# pse84_a0 register map
Vendor: Infineon Technologies; Series: PSE84_A0; File version: 1.0
CPU: CM33 r0p1, little endian, MPU, FPU, VTOR, 3 interrupt priority bits
Registers are 32-bit, read-write, reset 0x0 unless marked. A register's access mark holds for its fields unless they carry their own. Offsets are from the block's base; [hi:lo] are bit positions; lines under a group give offsets from that group; {n}, {i} and the like mark numbered series.

## USBHS (part 2 of 7) — Regmap for both Subsystem and Controller IP
Base 0x44900000
0x00 DWC_OTG_INTREG group — Internal register map
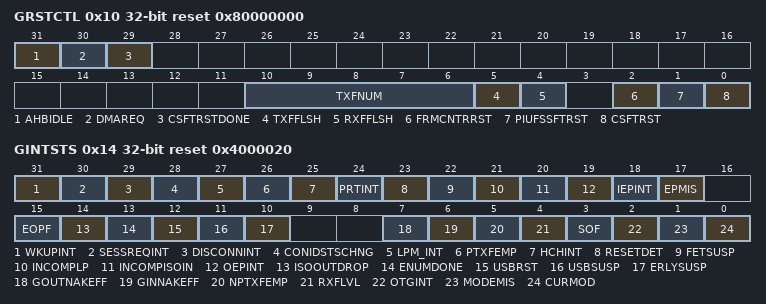
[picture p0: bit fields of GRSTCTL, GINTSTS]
  0x10 GRSTCTL reset 0x80000000 — The application uses this register to reset various hardware features inside the controller.
    [31] AHBIDLE ro — Mode: Host and Device AHB Master Idle (AHBIdle) Indicates that the AHB Master State Machine is in the IDLE condition.
      1=ACTIVE (AHB Master Idle); 0=INACTIVE (Not Idle)
    [30] DMAREQ ro — Mode: Host and Device DMA Request Signal (DMAReq) Indicates that the DMA request is in progress. Used for debug.
      1=ACTIVE (DMA request is in progress); 0=INACTIVE (No DMA request)
    [29] CSFTRSTDONE — Mode: Host and Device Core Soft Reset Done (CSftRstDone) The core sets this bit when all the necessary logic is reset in the core.This bit is cleared by the application along with GRSTCTL.CSftRst (bit 0)
      1=ACTIVE (Core Soft Reset is done); 0=INACTIVE (No reset)
    [10:6] TXFNUM — Mode: Host and Device TxFIFO Number (TxFNum) This is the FIFO number that must be flushed using the TxFIFO Flush bit. This field must not be changed until the core clears the TxFIFO Flush bit. - 5'h0: -- Non-periodic TxFIFO flush in Host mode -- Non-periodic TxFIFO flush in device mode when in shared FIFO operation -- Tx FIFO 0 flush in device mode when in dedicated FIFO mode - 5'h1: -- Periodic TxFIFO flush in Host mode -- Periodic TxFIFO 1 flush in Device mode when in shared FIFO operation -- TXFIFO 1 flush in device mode when in dedicated FIFO mode - 5'h2: -- Periodic TxFIFO 2 flush in Device mode when in shared FIFO operation -- TXFIFO 2 flush in device mode when in dedicated FIFO mode ... - 5'hF -- Periodic TxFIFO 15 flush in Device mode when in shared FIFO operation -- TXFIFO 15 flush in device mode when in dedicated FIFO mode - 5'h10: Flush all the transmit FIFOs in device or host mode
      0=TXF0 (<ct:DWC_DESIGN_ID==0>-Periodic TxFIFO flush in host mode -Periodic TxFIFO 0 flush in device mode when in shared FIFO operation -</ct>TXFIFO 0 flush in device mode when in dedicated FIFO mode); 1=TXF1 (<ct:DWC_DESIGN_ID==0>-Periodic TxFIFO flush in host mode -Periodic TxFIFO 1 flush in device mode when in shared FIFO operation -</ct>TXFIFO 1 flush in device mode when in dedicated FIFO mode); {v}=TXF{v} (-Periodic TxFIFO {v} flush in device mode when in shared FIFO operation -TXFIFO {v} flush in device mode when in dedicated FIFO mode) (v=9..12); 13=TXF13 (-Periodic TxFIFO 13 flush in Device mode when in shared FIFO operation -TXFIFO 13 flush in device mode when in dedicated FIFO mode); 14=TXF14 (-Periodic TxFIFO 14 flush in Device mode when in shared FIFO operation -TXFIFO 14 flush in device mode when in dedicated FIFO mode); 15=TXF15 (-Periodic TxFIFO 15 flush in Device mode when in shared FIFO operation - TXFIFO 15 flush in device mode when in dedicated FIFO mode); 16=TXF16 (Flush all the transmit FIFOs<ct:DWC_DESIGN_ID==0> in device or host mode</ct>); {v}=TXF{v} (<ct:DWC_DESIGN_ID==0>-Periodic TxFIFO {v} flush in device mode when in shared FIFO operation -</ct>TXFIFO {v} flush in device mode when in dedicated FIFO mode) (v=2..8)
    [5] TXFFLSH — Mode: Host and Device TxFIFO Flush (TxFFlsh) This bit selectively flushes a single or all transmit FIFOs, but cannot do so If the core is in the midst of a transaction. The application must write this bit only after checking that the core is neither writing to the TxFIFO nor reading from the TxFIFO. Verify using these registers: - ReadNAK Effective Interrupt ensures the core is not reading from the FIFO - WriteGRSTCTL.AHBIdle ensures the core is not writing anything to the FIFO. Flushing is normally recommended when FIFOs are reconfigured or when switching between Shared FIFO and Dedicated Transmit FIFO operation. FIFO flushing is also recommended during device endpoint disable. The application must wait until the core clears this bit before performing any operations. This bit takes eight clocks to clear, using the slower clock of phy_clk or hclk.
      1=ACTIVE (Selectively flushes a single or all transmit FIFOs); 0=INACTIVE (No Flush)
    [4] RXFFLSH — Mode: Host and Device RxFIFO Flush (RxFFlsh) The application can flush the entire RxFIFO using this bit, but must first ensure that the core is not in the middle of a transaction. The application must only write to this bit after checking that the controller is neither reading from the RxFIFO nor writing to the RxFIFO. The application must wait until the bit is cleared before performing any other operations. This bit requires eight clocks (slowest of PHY or AHB clock) to clear.
      1=ACTIVE (Flushes the entire RxFIFO); 0=INACTIVE (Does not flush the entire RxFIFO)
    [2] FRMCNTRRST — Mode: Host only Host Frame Counter Reset (FrmCntrRst) The application writes this bit to reset the (micro)Frame number counter inside the core. When the (micro)Frame counter is reset, the subsequent SOF sent out by the core has a (micro)Frame number of 0. When application writes 1 to the bit, it might not be able to read back the value as it will get cleared by the core in a few clock cycles.
      1=ACTIVE (Host Frame Counter Reset); 0=NOTACTIVE (No reset)
    [1] PIUFSSFTRST — Mode: Host and Device PIU FS Dedicated Controller Soft Reset (PIUFSSftRst) Resets the PIU FS Dedicated Controller All module state machines in FS Dedicated Controller of PIU are reset to the IDLE state. Used to reset the FS Dedicated controller in PIU in case of any PHY Errors like Loss of activity or Babble Error resulting in the PHY remaining in RX state for more than one frame boundary. This is a self clearing bit and core clears this bit after all the necessary logic is reset in the core.
      1=RESET_ACTIVE (PIU FS Dedicated Controller Soft Reset); 0=RESET_INACTIVE (No Reset)
    [0] CSFTRST — Mode: Host and Device Core Soft Reset (CSftRst) Resets the hclk and phy_clock domains as follows: - Clears the interrupts and all the CSR registers except the following register bits: -- PCGCCTL.RstPdwnModule -- PCGCCTL.GateHclk -- PCGCCTL.PwrClmp -- PCGCCTL.StopPPhyLPwrClkSelclk -- GUSBCFG.ForceDevMode -- GUSBCFG.ForceHstMode -- GUSBCFG.PhyLPwrClkSel -- GUSBCFG.DDRSel -- GUSBCFG.PHYSel -- GUSBCFG.FSIntf -- GUSBCFG.ULPI_UTMI_Sel -- GUSBCFG.PHYIf -- GUSBCFG.TxEndDelay -- GUSBCFG.TermSelDLPulse -- GUSBCFG.ULPIClkSusM -- GUSBCFG.ULPIAutoRes -- GUSBCFG.ULPIFsLs -- GGPIO -- GPWRDN -- GADPCTL -- HCFG.FSLSPclkSel -- DCFG.DevSpd -- DCTL.SftDiscon - All module state machines - All module state machines (except the AHB Slave Unit) are reset to the IDLE state, and all the transmit FIFOs and the receive FIFO are flushed. - Any transactions on the AHB Master are terminated as soon as possible, after gracefully completing the last data phase of an AHB transfer. Any transactions on the USB are terminated immediately. - When Hibernation or ADP feature is enabled, the PMU module is not reset by the Core Soft Reset. The application can write to this bit any time it wants to reset the core. The application must clear this bit after checking the bit 29 of this regiser (Core Soft Reset Done). Software must also must check that bit 31 of this register is 1 (AHB Master is IDLE) before starting any operation. Typically software reset is used during software development and also when you dynamically change the PHY selection bits in the USB configuration registers listed above. When you change the PHY, the corresponding clock for the PHY is selected and used in the PHY domain. Once a new clock is selected, the PHY domain has to be reset for proper operation.
      1=ACTIVE (Resets hclk and phy_clock domains); 0=NOTACTIVE (No reset)
  0x14 GINTSTS reset 0x4000020 — This register interrupts the application for system-level events in the current mode (Device mode or Host mode). Some of the bits in this register are valid only in Host mode, while others are valid in Device mode only. This register also indicates the current mode. To clear the interrupt status bits of type R_SS_WC, the application must write 1'b1 to the bit. The FIFO status interrupts are read only; once software reads from or writes to the FIFO while servicing these interrupts, FIFO interrupt conditions are cleared automatically. The application must clear the GINTSTS register at initialization before unmasking the interrupt bit to avoid any interrupts generated prior to initialization. Note: Read the reset value of GINTSTS.CurMod only after the following conditions: - If IDDIG_FILTER is disabled, read only after PHY clock is stable. - If IDDIG_FILTER is enabled, read only after the filter timer expires.
    [31] WKUPINT — Mode: Host and Device Resume/Remote Wakeup Detected Interrupt (WkUpInt) Wakeup Interrupt during Suspend(L2) or LPM(L1) state. - During Suspend(L2): -- Device Mode: This interrupt is asserted only when Host Initiated Resume is detected on USB. -- Host Mode: This interrupt is asserted only when Device Initiated Remote Wakeup is detected on USB. For more information, see 'Partial Power-Down and Clock Gating Programming Model' in the Programming Guide. - During LPM(L1): -- Device Mode: This interrupt is asserted for either Host Initiated Resume or Device Initiated Remote Wakeup on USB. -- Host Mode: This interrupt is asserted for either Host Initiated Resume or Device Initiated Remote Wakeup on USB. For more information, see 'LPM Entry and Exit Programming Model' in the Programming Guide.
      1=ACTIVE (Resume or Remote Wakeup Detected Interrupt); 0=INACTIVE (Not active)
    [30] SESSREQINT — Mode: Host and Device Session Request/New Session Detected Interrupt (SessReqInt) In Host mode, this interrupt is asserted when a session request is detected from the device. In Host mode, this interrupt is asserted when a session request is detected from the device. In Device mode, this interrupt is asserted when the utmisrp_bvalid signal goes high. For more information on how to use this interrupt, see 'Partial Power-Down and Clock Gating Programming Model' in the Programming Guide.
      1=ACTIVE (Session Request New Session Detected Interrupt); 0=INACTIVE (Not active)
    [29] DISCONNINT — Mode: Host only Disconnect Detected Interrupt (DisconnInt) Asserted when a device disconnect is detected.
      1=ACTIVE (Disconnect Detected Interrupt); 0=INACTIVE (Not active)
    [28] CONIDSTSCHNG — Mode: Host and Device Connector ID Status Change (ConIDStsChng) The core sets this bit when there is a change in connector ID status.
      1=ACTIVE (Connector ID Status Change); 0=INACTIVE (Not Active)
    [27] LPM_INT — Mode: Host and Device LPM Transaction Received Interrupt (LPM_Int). - Device Mode: This interrupt is asserted when the device receives an LPM transaction and responds with a non-ERRORed response. - Host Mode: This interrupt is asserted when the device responds to an LPM transaction with a non-ERRORed response or when the host core has completed LPM transactions for the programmed number of times (GLPMCFG.RetryCnt).
      1=ACTIVE (LPM Transaction Received Interrupt); 0=INACTIVE (Not Active)
    [26] PTXFEMP ro — Mode: Host only Periodic TxFIFO Empty (PTxFEmp) This interrupt is asserted when the Periodic Transmit FIFO is either half or completely empty and there is space for at least one entry to be written in the Periodic Request Queue. The half or completely empty status is determined by the Periodic TxFIFO Empty Level bit in the Core AHB Configuration register (GAHBCFG.PTxFEmpLvl).
      1=ACTIVE (Periodic TxFIFO Empty); 0=INACTIVE (Not active)
    [25] HCHINT ro — Mode: Host only Host Channels Interrupt (HChInt) The core sets this bit to indicate that an interrupt is pending on one of the channels of the core (in Host mode). The application must read the Host All Channels Interrupt (HAINT) register to determine the exact number of the channel on which the interrupt occurred, and Then read the corresponding Host Channel-n Interrupt (HCINTn) register to determine the exact cause of the interrupt. The application must clear the appropriate status bit in the HCINTn register to clear this bit.
      1=ACTIVE (Host Channels Interrupt); 0=INACTIVE (Not active)
    [24] PRTINT ro — Mode: Host only Host Port Interrupt (PrtInt) The core sets this bit to indicate a change in port status of one of the controller ports in Host mode. The application must read the Host Port Control and Status (HPRT) register to determine the exact event that caused this interrupt. The application must clear the appropriate status bit in the Host Port Control and Status register to clear this bit.
      1=ACTIVE (Host Port Interrupt); 0=INACTIVE (Not active)
    [23] RESETDET — Mode: Device only Reset detected Interrupt (ResetDet) In Device mode, this interrupt is asserted when a reset is detected on the USB in partial power-down mode when the device is in Suspend. In Host mode, this interrupt is not asserted.
      1=ACTIVE (Reset detected Interrupt); 0=INACTIVE (Not active)
    [22] FETSUSP — Mode: Device only Data Fetch Suspended (FetSusp) This interrupt is valid only in DMA mode. This interrupt indicates that the core has stopped fetching data. For IN endpoints due to the unavailability of TxFIFO space or Request Queue space. This interrupt is used by the application for an endpoint mismatch algorithm. For example, after detecting an endpoint mismatch, the application: - Sets a Global non-periodic IN NAK handshake - Disables IN endpoints - Flushes the FIFO - Determines the token sequence from the IN Token Sequence Learning Queue - Re-enables the endpoints - Clears the Global non-periodic IN NAK handshake If the Global non-periodic IN NAK is cleared, the core has not yet fetched data for the IN endpoint, and the IN token is received. The core generates an 'IN token received when FIFO empty' interrupt. It then sends the host a NAK response. To avoid this scenario, the application can check the GINTSTS.FetSusp interrupt, which ensures that the FIFO is full before clearing a Global NAK handshake. Alternatively, the application can mask the IN token received when FIFO empty interrupt when clearing a Global IN NAK handshake.
      1=ACTIVE (Data Fetch Suspended); 0=INACTIVE (Not active)
    [21] INCOMPLP — Incomplete Periodic Transfer (incomplP) Mode: Host only In Host mode, the core sets this interrupt bit when there are incomplete periodic transactions still pending which are scheduled for the current microframe. Incomplete Isochronous OUT Transfer (incompISOOUT) Mode: Device only The Device mode, the core sets this interrupt to indicate that there is at least one isochronous OUT endpoint on which the transfer is not completed in the current microframe. This interrupt is asserted along with the End of Periodic Frame Interrupt (EOPF) bit in this register.
      1=ACTIVE (Incomplete Periodic Transfer); 0=INACTIVE (Not active)
    [20] INCOMPISOIN — Mode: Device only Incomplete Isochronous IN Transfer (incompISOIN) The core sets this interrupt to indicate that there is at least one isochronous IN endpoint on which the transfer is not completed in the current microframe. This interrupt is asserted along with the End of Periodic Frame Interrupt (EOPF) bit in this register. Note: This interrupt is not asserted in Scatter/Gather DMA mode.
      1=ACTIVE (Incomplete Isochronous IN Transfer); 0=INACTIVE (Not active)
    [19] OEPINT ro — Mode: Device only OUT Endpoints Interrupt (OEPInt) The controller sets this bit to indicate that an interrupt is pending on one of the OUT endpoints of the core (in Device mode). The application must read the Device All Endpoints Interrupt (DAINT) register to determine the exact number of the OUT endpoint on which the interrupt occurred, and then read the corresponding Device OUT Endpoint-n Interrupt (DOEPINTn) register to determine the exact cause of the interrupt. The application must clear the appropriate status bit in the corresponding DOEPINTn register to clear this bit.
      1=ACTIVE (OUT Endpoints Interrupt); 0=INACTIVE (Not active)
    [18] IEPINT ro — Mode: Device only IN Endpoints Interrupt (IEPInt) The core sets this bit to indicate that an interrupt is pending on one of the IN endpoints of the core (in Device mode). The application must read the Device All Endpoints Interrupt (DAINT) register to determine the exact number of the IN endpoint on Device IN Endpoint-n Interrupt (DIEPINTn) register to determine the exact cause of the interrupt. The application must clear the appropriate status bit in the corresponding DIEPINTn register to clear this bit.
      1=ACTIVE (IN Endpoints Interrupt); 0=INACTIVE (Not active)
    [17] EPMIS — Mode: Device only Endpoint Mismatch Interrupt (EPMis) Note: This interrupt is valid only in shared FIFO operation. Indicates that an IN token has been received for a non-periodic endpoint, but the data for another endpoint is present in the top of the Non-periodic Transmit FIFO and the IN endpoint mismatch count programmed by the application has expired.
      1=ACTIVE (Endpoint Mismatch Interrupt); 0=INACTIVE (Not active)
    [15] EOPF — Mode: Device only End of Periodic Frame Interrupt (EOPF) Indicates that the period specified in the Periodic Frame Interval field of the Device Configuration register (DCFG.PerFrInt) has been reached in the current microframe. In case of Non-Ignore Frame Number Scatter/Gather (Descriptor DMA) mode, the controller internally handles the following scenarios based on EOPF: Read Flush: At the EOPF, the controller checks if there are any pending packets in the FIFO corresponding to the current (micro)Frame. - If there are any pending packets, then the controller initiates read flush, due to which the read pointer is updated to the starting location of the next micro-frame packet. - If there are no pending packets corresponding to the current (micro)Frame, the controller does not take any action. Write Flush: At the EOPF, if the controller is still fetching the current micro-frame data, then the controller stops pushing data into the TXFIFO but keeps fetching the complete packet from the System Memory. After completing the scheduled packet size fetch, the controller updates the Status Quadlet Fields (Transmit Status to BUFFLUSH) and closes the Descriptor. During the descriptor close, the controller initiates write flush, due to which the write pointer is updated to the starting location of the next micro-frame packet. Because the controller stops pushing the packet to the TxFIFO after EOPF, to bring the write pointer to the starting location of the next micro-frame, write flush is done.
      1=ACTIVE (End of Periodic Frame Interrupt); 0=INACTIVE (Not active)
    [14] ISOOUTDROP — Mode: Device only Isochronous OUT Packet Dropped Interrupt (ISOOutDrop) The controller sets this bit when it fails to write an isochronous OUT packet into the RxFIFO because the RxFIFO does not have enough space to accommodate a maximum packet size packet for the isochronous OUT endpoint.
      1=ACTIVE (Isochronous OUT Packet Dropped Interrupt); 0=INACTIVE (Not active)
    [13] ENUMDONE — Mode: Device only Enumeration Done (EnumDone) The core sets this bit to indicate that speed enumeration is complete. The application must read the Device Status (DSTS) register to obtain the enumerated speed.
      1=ACTIVE (Enumeration Done); 0=INACTIVE (Not active)
    [12] USBRST — Mode: Device only USB Reset (USBRst) The controller sets this bit to indicate that a reset is detected on the USB.
      1=ACTIVE (USB Reset); 0=INACTIVE (Not active)
    [11] USBSUSP — Mode: Device only USB Suspend (USBSusp) The controller sets this bit to indicate that a suspend was detected on the USB. The controller enters the Suspended state when there is no activity on the linestate signal for an extended period of time.
      1=ACTIVE (USB Suspend); 0=INACTIVE (Not Active)
    [10] ERLYSUSP — Mode: Device only Early Suspend (ErlySusp) The controller sets this bit to indicate that an Idle state has been detected on the USB for 3 ms.
      1=ACTIVE (3ms of Idle state detected); 0=INACTIVE (No Idle state detected)
    [7] GOUTNAKEFF ro — Mode: Device only Global OUT NAK Effective (GOUTNakEff) Indicates that the Set Global OUT NAK bit in the Device Control register (DCTL.SGOUTNak), Set by the application, has taken effect in the core. This bit can be cleared by writing the Clear Global OUT NAK bit in the Device Control register (DCTL.CGOUTNak).
      1=ACTIVE (Global OUT NAK Effective); 0=INACTIVE (Not Active)
    [6] GINNAKEFF ro — Mode: Device only Global IN Non-periodic NAK Effective (GINNakEff) Indicates that the Set Global Non-periodic IN NAK bit in the Device Control register (DCTL.SGNPInNak) set by the application, has taken effect in the core. That is, the core has sampled the Global IN NAK bit Set by the application. This bit can be cleared by clearing the Clear Global Non-periodic IN NAK bit in the Device Control register (DCTL.CGNPInNak). This interrupt does not necessarily mean that a NAK handshake is sent out on the USB. The STALL bit takes precedence over the NAK bit.
      1=ACTIVE (Set Global Non-periodic IN NAK bit); 0=INACTIVE (Global Non-periodic IN NAK not active)
    [5] NPTXFEMP ro — Mode: Host and Device Non-periodic TxFIFO Empty (NPTxFEmp) This interrupt is asserted when the Non-periodic TxFIFO is either half or completely empty, and there is space for at least one Entry to be written to the Non-periodic Transmit Request Queue. The half or completely empty status is determined by the Non-periodic TxFIFO Empty Level bit in the Core AHB Configuration register (GAHBCFG.NPTxFEmpLvl). In host mode, the application can use GINTSTS.NPTxFEmp with the OTG_EN_DED_TX_FIFO parameter set to either 1 or 0. In device mode, the application uses GINTSTS.NPTxFEmp when OTG_EN_DED_TX_FIFO=0. When OTG_EN_DED_TX_FIFO=1, the application uses DIEPINTn.TxFEmp.
      1=ACTIVE (Non-periodic TxFIFO is empty); 0=INACTIVE (Non-periodic TxFIFO is not empty)
    [4] RXFLVL ro — Mode: Host and Device RxFIFO Non-Empty (RxFLvl) Indicates that there is at least one packet pending to be read from the RxFIFO.
      1=ACTIVE (Rx Fifo is not empty); 0=INACTIVE (Rx Fifo is empty)
    [3] SOF — Mode: Host and Device Start of (micro)Frame (Sof) In Host mode, the core sets this bit to indicate that an SOF (FS), micro-SOF (HS), or Keep-Alive (LS) is transmitted on the USB. The application must write a 1 to this bit to clear the interrupt. In Device mode, the controller sets this bit to indicate that an SOF token has been received on the USB. The application can read the Device Status register to get the current (micro)Frame number. This interrupt is seen only when the core is operating at either HS or FS. This bit can be set only by the core and the application must write 1 to clear it. Note: This register may return 1'b1 if read immediately after power-on reset. If the register bit reads 1'b1 immediately after power-on reset, it does not indicate that an SOF has been sent (in case of host mode) or SOF has been received (in case of device mode). The read value of this interrupt is valid only after a valid connection between host and device is established. If the bit is set after power on reset the application can clear the bit.
      1=ACTIVE (Start of Frame); 0=INTACTIVE (No Start of Frame)
    [2] OTGINT ro — Mode: Host and Device OTG Interrupt (OTGInt) The controller sets this bit to indicate an OTG protocol event. The application must read the OTG Interrupt Status (GOTGINT) register to determine the exact event that caused this interrupt. The application must clear the appropriate status bit in the GOTGINT register to clear this bit.
      1=ACTIVE (OTG Interrupt); 0=INACTIVE (No Interrupt)
    [1] MODEMIS — Mode: Host and Device Mode Mismatch Interrupt (ModeMis) The core sets this bit when the application is trying to access: - A Host mode register, when the controller is operating in Device mode - A Device mode register, when the controller is operating in Host mode The register access is completed on the AHB with an OKAY response, but is ignored by the controller internally and does not affect the operation of the controller. This bit can be set only by the core and the application should write 1 to clear it.
      1=ACTIVE (Mode Mismatch Interrupt); 0=INACTIVE (No Mode Mismatch Interrupt)
    [0] CURMOD ro — Mode: Host and Device Current Mode of Operation (CurMod) Indicates the current mode. - 1'b0: Device mode - 1'b1: Host mode Note: The reset value of this register field can be read only after the PHY clock is stable, or if IDDIG_FILTER is enabled, wait for the filter timer to expire to read the correct reset value which ever event is later.
      0=DEVICE (Device mode); 1=HOST (Host mode)
